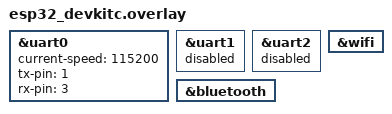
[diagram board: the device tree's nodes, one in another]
/*
 * Device Tree Overlay for Freenove ESP32 Dog Robot
 * Board: esp32_devkitc
 * Hardware: ESP32-WROVER with OV2640 Camera
 * 
 * This file configures all the GPIO pins according to 
 * Freenove's official hardware layout.
 */

 // ============================================
// UART0 - Console/Debug Output
// ============================================
&uart0 {
    status = "okay";
    current-speed = <115200>;
    tx-pin = <1>;   // GPIO 1 = TX
    rx-pin = <3>;   // GPIO 3 = RX
};

// Disable unused UARTs
&uart1 {
    status = "disabled";
};

&uart2 {
    status = "disabled";
};

 // ============================================
// WiFi and Bluetooth
// ============================================
&wifi {
    status = "okay";
};

&bluetooth {
    status = "okay";
};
